# CY8C5888LTI_LP097 register map
File version: 0.1
Registers are 8-bit, read-write, no defined reset value unless marked. A register's access mark holds for its fields unless they carry their own. Offsets are from the block's base; [hi:lo] are bit positions; {n}, {i} and the like mark numbered series; 'fields as' and 'values as' point back to an identical list.

## ADC_SAR_1 — SAR ADC
Base 0x00000000
0x40004616 SAR_TR0 — SAR trim register
{0x40005908+i} SAR_CSR{i} (i=0..6) — SAR status and control register {i}
0x40005B28 SAR_SW0 — SAR Analog Routing Register 0
{0x40005B28+i} SAR_SW{i} (i=2..4) — SAR Analog Routing Register {i}
0x40005B2E SAR_SW6 — SAR Analog Routing Register 6
0x40005B2F SAR_CLK — SAR Clock Selection Register
0x40005BA2 SAR_WRK 16-bit — SAR working register

## PWM2
Base 0x00000000
0x40006421 PWM2_COMPARE_Reg_ — UDB.D0 - Assigned Compare Value
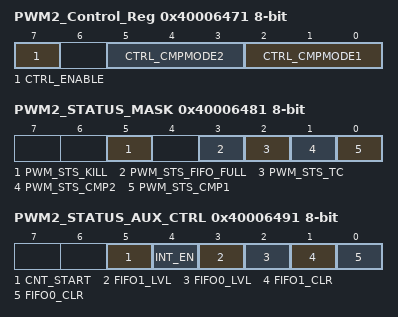
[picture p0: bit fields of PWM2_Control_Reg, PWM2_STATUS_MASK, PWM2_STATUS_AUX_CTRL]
0x40006471 PWM2_Control_Reg — UDB Control Register - Assigned Control Register Value
  [7] CTRL_ENABLE — Enable the PWM
  [5:3] CTRL_CMPMODE2 — Compare mode 2
  [2:0] CTRL_CMPMODE1 — Compare mode 1
0x40006481 PWM2_STATUS_MASK — UDB Status bits Interrupt Mask Enable Register
  [5] PWM_STS_KILL ro — Enables the Interrupt on Kill
  [3] PWM_STS_FIFO_FULL ro — FIFO Full Status Mask
  [2] PWM_STS_TC ro — Enables the Interrupt on Terminal Count
  [1] PWM_STS_CMP2 ro — Enables the Interrupt on Compare 2
  [0] PWM_STS_CMP1 ro — Enables the Interrupt on Compare 1
0x40006491 PWM2_STATUS_AUX_CTRL — UDB Auxilliary Control Register
  [5] CNT_START — FIFO0 clear
    0=E_CNT_START0 (Disable counter); 1=E_CNT_START1 (Enable counter)
  [4] INT_EN
    0=E_INT_EN0 (Interrupt disabled); 1=E_INT_EN1 (Interrupt enabled)
  [3] FIFO1_LVL — FIFO level
    0=E_FIFO_LVL_0 (FIFO LVL: input mode: FIFO not full; output mode: FIFO not empty); 1=E_FIFO_LVL_1 (FIFO LVL: input mode: FIFO at least 1/2 empty; output mode: FIFO at least 1/2 full)
  [2] FIFO0_LVL — FIFO level
    values as FIFO1_LVL
  [1] FIFO1_CLR — FIFO1 clear
    0=E_FIFO_CLR_0 (Normal FIFO operation); 1=E_FIFO_CLR_1 (Clear FIFO state)
  [0] FIFO0_CLR — FIFO0 clear
    values as FIFO1_CLR

## Control_Reg
Base 0x00000000
0x40006477 Control_Reg_CONTROL_REG

## Timer
Base 0x00000000
0x40006506 Timer_COUNTER 16-bit — UDB.A0 - Current Down Counter Value
0x40006526 Timer_PERIOD 16-bit — UDB.D0 - Assigned Period
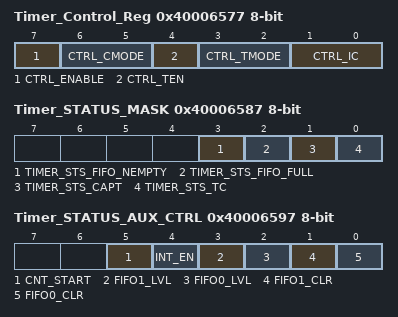
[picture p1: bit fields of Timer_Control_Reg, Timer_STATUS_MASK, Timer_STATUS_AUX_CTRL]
0x40006577 Timer_Control_Reg — UDB Control Register - Assigned Control Register Value
  [7] CTRL_ENABLE — Enable the Timer
  [6:5] CTRL_CMODE — Capture Mode
  [4] CTRL_TEN — Trigger Enable Bit
  [3:2] CTRL_TMODE — Trigger Mode
  [1:0] CTRL_IC — Interrupt Count
0x40006587 Timer_STATUS_MASK — UDB Status bits Interrupt Mask Enable Register
  [3] TIMER_STS_FIFO_NEMPTY ro — FIFO Empty status
  [2] TIMER_STS_FIFO_FULL ro — FIFO Full Status
  [1] TIMER_STS_CAPT ro — Enables the Interrupt on Capture
  [0] TIMER_STS_TC ro — Enables the Interrupt on TC
0x40006597 Timer_STATUS_AUX_CTRL — UDB Auxilliary Control Register
  [5] CNT_START — FIFO0 clear
    0=E_CNT_START0 (Disable counter); 1=E_CNT_START1 (Enable counter)
  [4] INT_EN
    0=E_INT_EN0 (Interrupt disabled); 1=E_INT_EN1 (Interrupt enabled)
  [3] FIFO1_LVL — FIFO level
    0=E_FIFO_LVL_0 (FIFO LVL: input mode: FIFO not full; output mode: FIFO not empty); 1=E_FIFO_LVL_1 (FIFO LVL: input mode: FIFO at least 1/2 empty; output mode: FIFO at least 1/2 full)
  [2] FIFO0_LVL — FIFO level
    values as FIFO1_LVL
  [1] FIFO1_CLR — FIFO1 clear
    0=E_FIFO_CLR_0 (Normal FIFO operation); 1=E_FIFO_CLR_1 (Clear FIFO state)
  [0] FIFO0_CLR — FIFO0 clear
    values as FIFO1_CLR

## Counter
Base 0x00000000
0x40006504 Counter_COUNTER 16-bit — UDB.A0 - Current Counter Value
0x40006524 Counter_PERIOD 16-bit — UDB.D0 - Assigned Period
0x40006534 Counter_COMPARE 16-bit — UDB.D1 - Assigned Compare Value
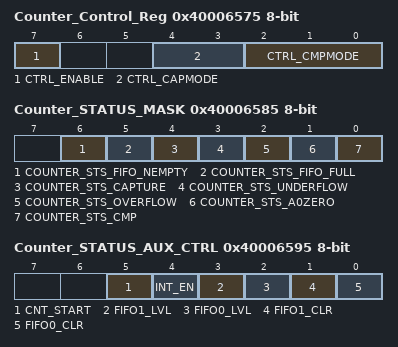
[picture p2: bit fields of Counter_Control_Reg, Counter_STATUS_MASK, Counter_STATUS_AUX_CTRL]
0x40006575 Counter_Control_Reg — UDB Control Register - Assigned Control Register Value
  [7] CTRL_ENABLE — Enable Counter
  [4:3] CTRL_CAPMODE — Capture mode
  [2:0] CTRL_CMPMODE — Compare mode
0x40006585 Counter_STATUS_MASK — UDB Status bits Interrupt Mask Enable Register
  [6] COUNTER_STS_FIFO_NEMPTY — FIFO Not Empty Status
  [5] COUNTER_STS_FIFO_FULL — FIFO Full Status
  [4] COUNTER_STS_CAPTURE — Capture Status
  [3] COUNTER_STS_UNDERFLOW — Underflow status
  [2] COUNTER_STS_OVERFLOW — Overflow status
  [1] COUNTER_STS_A0ZERO — A0 Zero ouput status
  [0] COUNTER_STS_CMP — Compare output status
0x40006595 Counter_STATUS_AUX_CTRL — UDB Auxilliary Control Register
  [5] CNT_START — FIFO0 clear
    0=E_CNT_START0 (Disable counter); 1=E_CNT_START1 (Enable counter)
  [4] INT_EN
    0=E_INT_EN0 (Interrupt disabled); 1=E_INT_EN1 (Interrupt enabled)
  [3] FIFO1_LVL — FIFO level
    0=E_FIFO_LVL_0 (FIFO LVL: input mode: FIFO not full; output mode: FIFO not empty); 1=E_FIFO_LVL_1 (FIFO LVL: input mode: FIFO at least 1/2 empty; output mode: FIFO at least 1/2 full)
  [2] FIFO0_LVL — FIFO level
    values as FIFO1_LVL
  [1] FIFO1_CLR — FIFO1 clear
    0=E_FIFO_CLR_0 (Normal FIFO operation); 1=E_FIFO_CLR_1 (Clear FIFO state)
  [0] FIFO0_CLR — FIFO0 clear
    values as FIFO1_CLR
